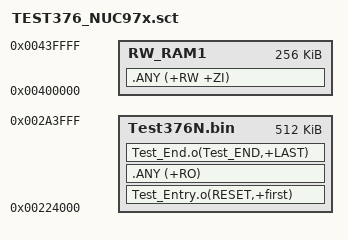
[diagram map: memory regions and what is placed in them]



LOAD_Test 0x00224000 0x00080000;//256
{
  Test376N.bin 0x00224000 0x00080000
  {
;//Entry
		Test_Entry.o(RESET,+first)
		;//*(InRoot$$Sections);//__main()的一部分
    .ANY (+RO)
		
;//End
		Test_End.o(Test_END,+LAST)
  }
	
	RW_RAM1 0x00400000 0x00040000;//+0;RW_RAM1 start address is after ER_ROM1
	{
		.ANY (+RW +ZI)
	}
	;//ARM_LIB_HEAP  0x00100000 EMPTY  0x00080000   {}
	;//ARM_LIB_STACK 0x00180000 EMPTY -0x00080000   {}
}



